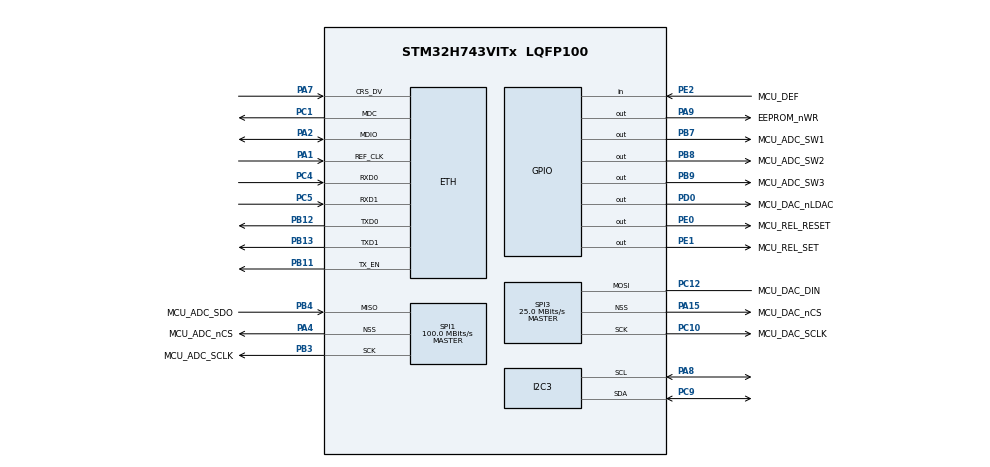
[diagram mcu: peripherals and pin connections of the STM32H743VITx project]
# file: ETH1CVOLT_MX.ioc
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CORTEX_M7.AccessPermission_S-Cortex_Memory_Protection_Unit_Region1_Settings_S=MPU_REGION_FULL_ACCESS
CORTEX_M7.BaseAddress_S-Cortex_Memory_Protection_Unit_Region1_Settings_S=0x24000000
CORTEX_M7.CPU_DCache=Enabled
CORTEX_M7.CPU_ICache=Enabled
CORTEX_M7.DisableExec_S-Cortex_Memory_Protection_Unit_Region1_Settings_S=MPU_INSTRUCTION_ACCESS_DISABLE
CORTEX_M7.Enable_S-Cortex_Memory_Protection_Unit_Region1_Settings_S=MPU_REGION_ENABLE
CORTEX_M7.Enable_S-Cortex_Memory_Protection_Unit_Region2_Settings_S=__NULL
CORTEX_M7.Enable_Spec=MPU_REGION_ENABLE
CORTEX_M7.IsCacheable_S-Cortex_Memory_Protection_Unit_Region1_Settings_S=MPU_ACCESS_NOT_CACHEABLE
CORTEX_M7.IsShareable_S-Cortex_Memory_Protection_Unit_Region1_Settings_S=MPU_ACCESS_NOT_SHAREABLE
CORTEX_M7.Size_S-Cortex_Memory_Protection_Unit_Region1_Settings_S=MPU_REGION_SIZE_512KB
CORTEX_M7.TypeExtField_S-Cortex_Memory_Protection_Unit_Region1_Settings_S=MPU_TEX_LEVEL1
CORTEX_M7.default_mode_Activation=1
ETH.MediaInterface=HAL_ETH_RMII_MODE
ETH.RxBufferAddress=0x24030000
ETH.RxDescAddress=0x24030000
ETH.TxDescAddress=0x30020060
I2C3.Timing=0x10C0ECFF
Mcu.Family=STM32H7
Mcu.Name=STM32H743VITx
Mcu.Package=LQFP100
NVIC.ETH_IRQn=true\:7\:0\:true\:false\:true\:false\:true\:true\:true
NVIC.PriorityGroup=NVIC_PRIORITYGROUP_4
NVIC.TIM1_UP_IRQn=true\:1\:0\:true\:false\:true\:false\:false\:true\:true
NVIC.TimeBase=TIM1_UP_IRQn
NVIC.TimeBaseIP=TIM1
PA1.GPIO_Speed_Default_HIGH=GPIO_SPEED_FREQ_VERY_HIGH
PA1.Mode=RMII
PA1.Signal=ETH_REF_CLK
PA13\ (JTMS/SWDIO).Mode=Serial_Wire
PA13\ (JTMS/SWDIO).Signal=DEBUG_JTMS-SWDIO
PA14\ (JTCK/SWCLK).Mode=Serial_Wire
PA14\ (JTCK/SWCLK).Signal=DEBUG_JTCK-SWCLK
PA15\ (JTDI).GPIO_Label=MCU_DAC_nCS
PA15\ (JTDI).Mode=NSS_Signal_Hard_Output
PA15\ (JTDI).Signal=SPI3_NSS
PA2.GPIO_Speed_Default_HIGH=GPIO_SPEED_FREQ_VERY_HIGH
PA2.Mode=RMII
PA2.Signal=ETH_MDIO
PA4.GPIO_Label=MCU_ADC_nCS
PA4.Mode=NSS_Signal_Hard_Output
PA4.Signal=SPI1_NSS
PA7.GPIO_Speed_Default_HIGH=GPIO_SPEED_FREQ_VERY_HIGH
PA7.Mode=RMII
PA7.Signal=ETH_CRS_DV
PA8.Mode=I2C
PA8.Signal=I2C3_SCL
PA9.GPIO_Label=EEPROM_nWR
PA9.Signal=GPIO_Output
PB11.GPIO_Speed_Default_HIGH=GPIO_SPEED_FREQ_VERY_HIGH
PB11.Mode=RMII
PB11.Signal=ETH_TX_EN
PB12.GPIO_Speed_Default_HIGH=GPIO_SPEED_FREQ_VERY_HIGH
PB12.Mode=RMII
PB12.Signal=ETH_TXD0
PB13.GPIO_Speed_Default_HIGH=GPIO_SPEED_FREQ_VERY_HIGH
PB13.Mode=RMII
PB13.Signal=ETH_TXD1
PB3\ (JTDO/TRACESWO).GPIO_Label=MCU_ADC_SCLK
PB3\ (JTDO/TRACESWO).Mode=RX_Only_Simplex_Unidirect_Master
PB3\ (JTDO/TRACESWO).Signal=SPI1_SCK
PB4\ (NJTRST).GPIO_Label=MCU_ADC_SDO
PB4\ (NJTRST).Mode=RX_Only_Simplex_Unidirect_Master
PB4\ (NJTRST).Signal=SPI1_MISO
PB7.GPIO_Label=MCU_ADC_SW1
PB7.Signal=GPIO_Output
PB8.GPIO_Label=MCU_ADC_SW2
PB8.Signal=GPIO_Output
PB9.GPIO_Label=MCU_ADC_SW3
PB9.Signal=GPIO_Output
PC1.GPIO_Speed_Default_HIGH=GPIO_SPEED_FREQ_VERY_HIGH
PC1.Mode=RMII
PC1.Signal=ETH_MDC
PC10.GPIO_Label=MCU_DAC_SCLK
PC10.Mode=Simplex_Bidirectional_Master
PC10.Signal=SPI3_SCK
PC12.GPIO_Label=MCU_DAC_DIN
PC12.Mode=Simplex_Bidirectional_Master
PC12.Signal=SPI3_MOSI
PC4.GPIO_Speed_Default_HIGH=GPIO_SPEED_FREQ_VERY_HIGH
PC4.Mode=RMII
PC4.Signal=ETH_RXD0
PC5.GPIO_Speed_Default_HIGH=GPIO_SPEED_FREQ_VERY_HIGH
PC5.Mode=RMII
PC5.Signal=ETH_RXD1
PC9.Mode=I2C
PC9.Signal=I2C3_SDA
PD0.GPIO_Label=MCU_DAC_nLDAC
PD0.Signal=GPIO_Output
PE0.GPIO_Label=MCU_REL_RESET
PE0.Signal=GPIO_Output
PE1.GPIO_Label=MCU_REL_SET
PE1.Signal=GPIO_Output
PE2.GPIO_Label=MCU_DEF
PE2.Signal=GPIO_Input
PH0-OSC_IN\ (PH0).Mode=HSE-External-Oscillator
PH0-OSC_IN\ (PH0).Signal=RCC_OSC_IN
PH1-OSC_OUT\ (PH1).Mode=HSE-External-Oscillator
PH1-OSC_OUT\ (PH1).Signal=RCC_OSC_OUT
ProjectManager.HeapSize=0x200
ProjectManager.StackSize=0x400
ProjectManager.TargetToolchain=STM32CubeIDE
RCC.ADCFreq_Value=32250000
RCC.APB1Freq_Value=100000000
RCC.APB2Freq_Value=100000000
RCC.APB3Freq_Value=100000000
RCC.APB4Freq_Value=100000000
RCC.CortexFreq_Value=400000000
RCC.D1PPRE=RCC_APB3_DIV2
RCC.D2PPRE1=RCC_APB1_DIV2
RCC.D2PPRE2=RCC_APB2_DIV2
RCC.D3PPRE=RCC_APB4_DIV2
RCC.DIVM1=1
RCC.DIVN1=50
RCC.DIVQ1=4
RCC.DIVR1=11
RCC.HCLKFreq_Value=200000000
RCC.HPRE=RCC_HCLK_DIV2
RCC.HSE_VALUE=16000000
RCC.PLLFRACN=0
RCC.PLLSourceVirtual=RCC_PLLSOURCE_HSE
RCC.SYSCLKFreq_VALUE=400000000
RCC.SYSCLKSource=RCC_SYSCLKSOURCE_PLLCLK
RCC.USBFreq_Value=200000000
SPI1.CalculateBaudRate=100.0 MBits/s
SPI1.Direction=SPI_DIRECTION_2LINES_RXONLY
SPI1.Mode=SPI_MODE_MASTER
SPI1.VirtualNSS=VM_NSSHARD
SPI1.VirtualType=VM_MASTER
SPI3.BaudRatePrescaler=SPI_BAUDRATEPRESCALER_8
SPI3.CalculateBaudRate=25.0 MBits/s
SPI3.DataSize=SPI_DATASIZE_32BIT
SPI3.Direction=SPI_DIRECTION_1LINE
SPI3.Mode=SPI_MODE_MASTER
SPI3.VirtualNSS=VM_NSSHARD
SPI3.VirtualType=VM_MASTER
STMicroelectronics.X-CUBE-AZRTOS-H7.3.4.0.FileXCcFileOoSystemJjFileXJjCore=true
STMicroelectronics.X-CUBE-AZRTOS-H7.3.4.0.GENERATE_FILEX_INIT_CODE=false
STMicroelectronics.X-CUBE-AZRTOS-H7.3.4.0.Initialize_ICMP_protocol=true
STMicroelectronics.X-CUBE-AZRTOS-H7.3.4.0.Initialize_TCP_protocol=true
STMicroelectronics.X-CUBE-AZRTOS-H7.3.4.0.Initialize_UDP_protocol=true
STMicroelectronics.X-CUBE-AZRTOS-H7.3.4.0.InterfacesCcNetworkJjEthernetOoInterface=true
STMicroelectronics.X-CUBE-AZRTOS-H7.3.4.0.InterfacesCcNetworkJjEthernetOoPhyOoInterface=LAN8742IiPhyIiInterface
STMicroelectronics.X-CUBE-AZRTOS-H7.3.4.0.LX_NOR_SIM_BASE_ADDRESS=0x08100000
STMicroelectronics.X-CUBE-AZRTOS-H7.3.4.0.LX_NOR_SIM_FLASH_SIZE=10240
STMicroelectronics.X-CUBE-AZRTOS-H7.3.4.0.LX_NOR_SIM_SECTORS_PER_BLOCK=2
STMicroelectronics.X-CUBE-AZRTOS-H7.3.4.0.NX_APP_IP_INSTANCE_THREAD_SIZE=1024
STMicroelectronics.X-CUBE-AZRTOS-H7.3.4.0.NX_APP_MEM_POOL_SIZE=30720
STMicroelectronics.X-CUBE-AZRTOS-H7.3.4.0.NX_APP_PACKET_POOL_SIZE=10
STMicroelectronics.X-CUBE-AZRTOS-H7.3.4.0.NX_APP_THREAD_STACK_SIZE=1024
STMicroelectronics.X-CUBE-AZRTOS-H7.3.4.0.NX_ARP_DEFEND_BY_REPLY=true
STMicroelectronics.X-CUBE-AZRTOS-H7.3.4.0.NX_DISABLE_IPV6=true
STMicroelectronics.X-CUBE-AZRTOS-H7.3.4.0.NX_DISABLE_IPV6_DAD=true
STMicroelectronics.X-CUBE-AZRTOS-H7.3.4.0.NX_ENABLE_ARP_MAC_CHANGE_NOTIFICATION=false
STMicroelectronics.X-CUBE-AZRTOS-H7.3.4.0.NX_ENABLE_INTERFACE_CAPABILITY=true
STMicroelectronics.X-CUBE-AZRTOS-H7.3.4.0.NetXDuoCcNetworkJjNetXDuoJjAddonsOoDHCPOoClient=true
STMicroelectronics.X-CUBE-AZRTOS-H7.3.4.0.NetXDuoCcNetworkJjNetXDuoJjAddonsOoWebOoServer=true
STMicroelectronics.X-CUBE-AZRTOS-H7.3.4.0.NetXDuoCcNetworkJjNetXDuoJjAddonsOomDNS=true
STMicroelectronics.X-CUBE-AZRTOS-H7.3.4.0.NetXDuoCcNetworkJjNetXDuoJjNXOoCore=true
STMicroelectronics.X-CUBE-AZRTOS-H7.3.4.0.NetXDuo_Static_IP_address=192.168.1.12
STMicroelectronics.X-CUBE-AZRTOS-H7.3.4.0.STM32CubeIiBSPIiComponentsCcBoardOoPartJjETHPhyJjLAN8742=true
STMicroelectronics.X-CUBE-AZRTOS-H7.3.4.0.TX_APP_CREATION=1
STMicroelectronics.X-CUBE-AZRTOS-H7.3.4.0.TX_APP_GENERATE_INIT_CODE=true
STMicroelectronics.X-CUBE-AZRTOS-H7.3.4.0.TX_APP_STACK_SIZE=512
STMicroelectronics.X-CUBE-AZRTOS-H7.3.4.0.TX_APP_THREAD_PRIO=2
STMicroelectronics.X-CUBE-AZRTOS-H7.3.4.0.TX_THREAD_ENABLE_PERFORMANCE_INFO=1
STMicroelectronics.X-CUBE-AZRTOS-H7.3.4.0.ThreadXCcRTOSJjThreadXJjCore=true
STMicroelectronics.X-CUBE-AZRTOS-H7.3.4.0.ThreadXCcRTOSJjThreadXJjLowOoPowerOosupport=true
STMicroelectronics.X-CUBE-AZRTOS-H7.3.4.0.ThreadXCcRTOSJjThreadXJjPerformanceInfo=true
STMicroelectronics.X-CUBE-AZRTOS-H7.3.4.0.ThreadXCcRTOSJjThreadXJjTraceXOosupport=true
STMicroelectronics.X-CUBE-AZRTOS-H7.3.4.0_IsAnAzureRtosMw=true
VP_MEMORYMAP_VS_MEMORYMAP.Mode=CurAppReg
VP_STMicroelectronics.X-CUBE-AZRTOS-H7_VS_BoardOoPartJjSTM32CubeIiBSPIiComponents_3.4.0_3.4.0.Mode=BoardOoPartJjSTM32CubeIiBSPIiComponents
VP_STMicroelectronics.X-CUBE-AZRTOS-H7_VS_FileOoSystemJjFileX_6.4.0_3.4.0.Mode=FileOoSystemJjFileX
VP_STMicroelectronics.X-CUBE-AZRTOS-H7_VS_NetworkJjInterfaces_3.4.0_3.4.0.Mode=NetworkJjInterfaces
VP_STMicroelectronics.X-CUBE-AZRTOS-H7_VS_NetworkJjNetXDuo_6.4.0_3.4.0.Mode=NetworkJjNetXDuo
VP_STMicroelectronics.X-CUBE-AZRTOS-H7_VS_RTOSJjThreadX_6.4.0_3.4.0.Mode=RTOSJjThreadX
VP_SYS_VS_tim1.Mode=TIM1
board=custom

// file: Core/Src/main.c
/* USER CODE BEGIN Header */
/**
  ******************************************************************************
  * @file           : main.c
  * @brief          : Main program body
  ******************************************************************************
  * @attention
  *
  * Copyright (c) 2026 STMicroelectronics.
  * All rights reserved.
  *
  * This software is licensed under terms that can be found in the LICENSE file
  * in the root directory of this software component.
  * If no LICENSE file comes with this software, it is provided AS-IS.
  *
  ******************************************************************************
  */
/* USER CODE END Header */
#include "app_threadx.h"
#include "main.h"
#include "eth.h"
#include "i2c.h"
#include "spi.h"
#include "gpio.h"

void SystemClock_Config(void);
static void MPU_Config(void);

int main(void)
{

  /* MPU Configuration--------------------------------------------------------*/
  MPU_Config();

  /* Enable the CPU Cache */

  /* Enable I-Cache---------------------------------------------------------*/
  SCB_EnableICache();

  /* Enable D-Cache---------------------------------------------------------*/
  SCB_EnableDCache();

  /* MCU Configuration--------------------------------------------------------*/

  /* Reset of all peripherals, Initializes the Flash interface and the Systick. */
  HAL_Init();

  /* USER CODE BEGIN Init */
  HAL_Delay(100);
  /* USER CODE END Init */

  /* Configure the system clock */
  SystemClock_Config();

  /* Initialize all configured peripherals */
  MX_GPIO_Init();
  MX_SPI3_Init();
  MX_I2C3_Init();
  MX_SPI1_Init();
  MX_ETH_Init();

  MX_ThreadX_Init();

  /* We should never get here as control is now taken by the scheduler */

  /* Infinite loop */
  while (1)
  {

  }
}

void SystemClock_Config(void)
{
  LL_FLASH_SetLatency(LL_FLASH_LATENCY_2);
  while(LL_FLASH_GetLatency()!= LL_FLASH_LATENCY_2)
  {
  }
  LL_PWR_ConfigSupply(LL_PWR_LDO_SUPPLY);
  LL_PWR_SetRegulVoltageScaling(LL_PWR_REGU_VOLTAGE_SCALE1);
  while (LL_PWR_IsActiveFlag_VOS() == 0)
  {
  }
  LL_RCC_HSE_Enable();

   /* Wait till HSE is ready */
  while(LL_RCC_HSE_IsReady() != 1)
  {

  }
  LL_RCC_PLL_SetSource(LL_RCC_PLLSOURCE_HSE);
  LL_RCC_PLL1P_Enable();
  LL_RCC_PLL1Q_Enable();
  LL_RCC_PLL1R_Enable();
  LL_RCC_PLL1_SetVCOInputRange(LL_RCC_PLLINPUTRANGE_8_16);
  LL_RCC_PLL1_SetVCOOutputRange(LL_RCC_PLLVCORANGE_WIDE);
  LL_RCC_PLL1_SetM(1);
  LL_RCC_PLL1_SetN(50);
  LL_RCC_PLL1_SetP(2);
  LL_RCC_PLL1_SetQ(4);
  LL_RCC_PLL1_SetR(11);
  LL_RCC_PLL1_Enable();

   /* Wait till PLL is ready */
  while(LL_RCC_PLL1_IsReady() != 1)
  {
  }

   /* Intermediate AHB prescaler 2 when target frequency clock is higher than 80 MHz */
   LL_RCC_SetAHBPrescaler(LL_RCC_AHB_DIV_2);

  LL_RCC_SetSysClkSource(LL_RCC_SYS_CLKSOURCE_PLL1);

   /* Wait till System clock is ready */
  while(LL_RCC_GetSysClkSource() != LL_RCC_SYS_CLKSOURCE_STATUS_PLL1)
  {

  }
  LL_RCC_SetSysPrescaler(LL_RCC_SYSCLK_DIV_1);
  LL_RCC_SetAHBPrescaler(LL_RCC_AHB_DIV_2);
  LL_RCC_SetAPB1Prescaler(LL_RCC_APB1_DIV_2);
  LL_RCC_SetAPB2Prescaler(LL_RCC_APB2_DIV_2);
  LL_RCC_SetAPB3Prescaler(LL_RCC_APB3_DIV_2);
  LL_RCC_SetAPB4Prescaler(LL_RCC_APB4_DIV_2);
  LL_SetSystemCoreClock(400000000);

   /* Update the time base */
  if (HAL_InitTick (TICK_INT_PRIORITY) != HAL_OK)
  {
    Error_Handler();
  }
}

/* USER CODE BEGIN 4 */
void HAL_ETH_ErrorCallback(ETH_HandleTypeDef *heth)
{
    /* Check if the error is a Receive Buffer Unavailable (RBU) */
    if ((HAL_ETH_GetDMAError(heth) & ETH_DMACSR_RBU) != 0U)
    {
        /* Clear the RBU state by forcing a resume of the DMA reception */
        HAL_ETH_Start_IT(heth);
    }
}

/* USER CODE END 4 */

 /* MPU Configuration */

void MPU_Config(void)
{
  MPU_Region_InitTypeDef MPU_InitStruct = {0};

  /* Disables the MPU */
  HAL_MPU_Disable();

  /** Initializes and configures the Region and the memory to be protected
  */
  MPU_InitStruct.Enable = MPU_REGION_ENABLE;
  MPU_InitStruct.Number = MPU_REGION_NUMBER0;
  MPU_InitStruct.BaseAddress = 0x0;
  MPU_InitStruct.Size = MPU_REGION_SIZE_4GB;
  MPU_InitStruct.SubRegionDisable = 0x87;
  MPU_InitStruct.TypeExtField = MPU_TEX_LEVEL0;
  MPU_InitStruct.AccessPermission = MPU_REGION_NO_ACCESS;
  MPU_InitStruct.DisableExec = MPU_INSTRUCTION_ACCESS_DISABLE;
  MPU_InitStruct.IsShareable = MPU_ACCESS_SHAREABLE;
  MPU_InitStruct.IsCacheable = MPU_ACCESS_NOT_CACHEABLE;
  MPU_InitStruct.IsBufferable = MPU_ACCESS_NOT_BUFFERABLE;

  HAL_MPU_ConfigRegion(&MPU_InitStruct);

  /** Initializes and configures the Region and the memory to be protected
  */
  MPU_InitStruct.Number = MPU_REGION_NUMBER1;
  MPU_InitStruct.BaseAddress = 0x24000000;
  MPU_InitStruct.Size = MPU_REGION_SIZE_512KB;
  MPU_InitStruct.SubRegionDisable = 0x0;
  MPU_InitStruct.TypeExtField = MPU_TEX_LEVEL1;
  MPU_InitStruct.AccessPermission = MPU_REGION_FULL_ACCESS;
  MPU_InitStruct.IsShareable = MPU_ACCESS_NOT_SHAREABLE;

  HAL_MPU_ConfigRegion(&MPU_InitStruct);
  /* Enables the MPU */
  HAL_MPU_Enable(MPU_PRIVILEGED_DEFAULT);

}

void HAL_TIM_PeriodElapsedCallback(TIM_HandleTypeDef *htim)
{
  if (htim->Instance == TIM1)
  {
    HAL_IncTick();
  }
}

void Error_Handler(void)
{
  __disable_irq();
  while (1)
  {
  }
}
